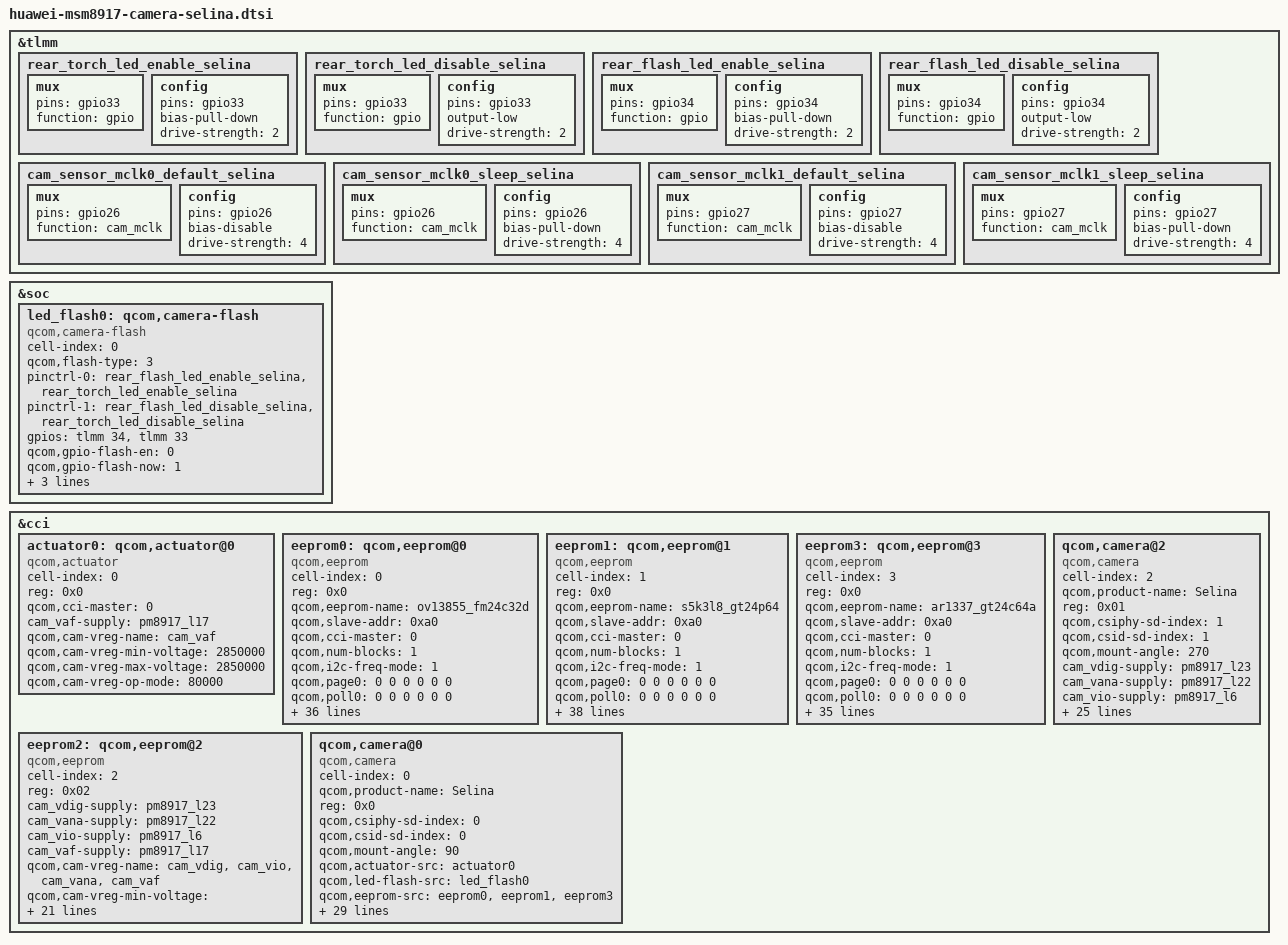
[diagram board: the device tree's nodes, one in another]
/*
 * Copyright (c) 2016, The Linux Foundation. All rights reserved.
 *
 * This program is free software; you can redistribute it and/or modify
 * it under the terms of the GNU General Public License version 2 and
 * only version 2 as published by the Free Software Foundation.
 *
 * This program is distributed in the hope that it will be useful,
 * but WITHOUT ANY WARRANTY; without even the implied warranty of
 * MERCHANTABILITY or FITNESS FOR A PARTICULAR PURPOSE.  See the
 * GNU General Public License for more details.
 */

&tlmm {
	rear_torch_led_enable_selina: rear_torch_led_enable_selina {
		mux {
			pins = "gpio33";
			function = "gpio";
		};

		config {
			pins = "gpio33";
			bias-pull-down; /* No PULL */
			drive-strength = <2>; /* 2 MA */
		};
	};

	rear_torch_led_disable_selina: rear_torch_led_disable_selina {
		mux {
			pins = "gpio33";
			function = "gpio";
		};

		config {
			pins = "gpio33";
			output-low; /* No PULL */
			drive-strength = <2>; /* 2 MA */
		};
	};

	rear_flash_led_enable_selina: rear_flash_led_enable_selina {
		mux {
			pins = "gpio34";
			function = "gpio";
		};

		config {
			pins = "gpio34";
			bias-pull-down; /* No PULL */
			drive-strength = <2>; /* 2 MA */
		};
	};

	rear_flash_led_disable_selina: rear_flash_led_disable_selina {
		mux {
			pins = "gpio34";
			function = "gpio";
		};

		config {
			pins = "gpio34";
			output-low; /* No PULL */
			drive-strength = <2>; /* 2 MA */
		};
	};

	cam_sensor_mclk0_default_selina: cam_sensor_mclk0_default_selina {
		/* MCLK0 */
		mux {
			/* CLK, DATA */
			pins = "gpio26";
			function = "cam_mclk";
		};

		config {
			pins = "gpio26";
			bias-disable; /* No PULL */
			drive-strength = <4>; /* 4 MA */
		};
	};

	cam_sensor_mclk0_sleep_selina: cam_sensor_mclk0_sleep_selina {
		/* MCLK0 */
		mux {
			/* CLK, DATA */
			pins = "gpio26";
			function = "cam_mclk";
		};

		config {
			pins = "gpio26";
			bias-pull-down; /* PULL DOWN */
			drive-strength = <4>; /* 4 MA */
		};
	};

	cam_sensor_mclk1_default_selina: cam_sensor_mclk1_default_selina {
		/* MCLK1 */
		mux {
			/* CLK, DATA */
			pins = "gpio27";
			function = "cam_mclk";
		};

		config {
			pins = "gpio27";
			bias-disable; /* No PULL */
			drive-strength = <4>; /* 4 MA */
		};
	};

	cam_sensor_mclk1_sleep_selina: cam_sensor_mclk1_sleep_selina {
		/* MCLK1 */
		mux {
			/* CLK, DATA */
			pins = "gpio27";
			function = "cam_mclk";
		};

		config {
			pins = "gpio27";
			bias-pull-down; /* PULL DOWN */
			drive-strength = <4>; /* 4 MA */
		};
	};

};

&soc {
	led_flash0: qcom,camera-flash {
		cell-index = <0>;
		compatible = "qcom,camera-flash";
		qcom,flash-type = <3>;
		pinctrl-names = "cam_default", "cam_suspend";
		pinctrl-0 = <&rear_flash_led_enable_selina &rear_torch_led_enable_selina>;
		pinctrl-1 = <&rear_flash_led_disable_selina &rear_torch_led_disable_selina>;
		gpios = <&tlmm 34 0>,
				<&tlmm 33 0>;
		qcom,gpio-flash-en = <0>;
		qcom,gpio-flash-now = <1>;
		qcom,gpio-req-tbl-num = <0 1>;
		qcom,gpio-req-tbl-flags = <0 0>;
		qcom,gpio-req-tbl-label = "FLASH_EN",
			"FLASH_NOW";
	};
};

&cci {
	actuator0: qcom,actuator@0 {
		cell-index = <0>;
		reg = <0x0>;
		compatible = "qcom,actuator";
		qcom,cci-master = <0>;
		cam_vaf-supply = <&pm8917_l17>;
		qcom,cam-vreg-name = "cam_vaf";
		qcom,cam-vreg-min-voltage = <2850000>;
		qcom,cam-vreg-max-voltage = <2850000>;
		qcom,cam-vreg-op-mode = <80000>;
	};

	eeprom0: qcom,eeprom@0 {
		cell-index = <0>;
		reg = <0x0>;
		qcom,eeprom-name = "ov13855_fm24c32d";
		compatible = "qcom,eeprom";

		qcom,slave-addr  = <0xa0>;
		qcom,cci-master = <0>;
		qcom,num-blocks = <1>;
		qcom,i2c-freq-mode = <1>;

		qcom,page0 = <0 0 0 0 0 0>;
		qcom,poll0 = <0 0 0 0 0 0>;
		qcom,mem0  = <2800 0x0000 2 0 1 0>;

		cam_vana-supply = <&pm8917_l22>;
		cam_vdig-supply = <&pm8917_l23>;
		cam_vio-supply = <&pm8917_l6>;
		cam_vaf-supply = <&pm8917_l17>;
		qcom,cam-vreg-name = "cam_vdig", "cam_vio", "cam_vana",
							"cam_vaf";
		qcom,cam-vreg-min-voltage = <1200000 1800000 2800000 2850000>;
		qcom,cam-vreg-max-voltage = <1200000 1800000 2800000 2850000>;
		qcom,cam-vreg-op-mode = <200000 80000 80000 100000>;
		pinctrl-names = "cam_default", "cam_suspend";
		pinctrl-0 = <&cam_sensor_mclk0_default_selina
				&cam_sensor_rear_default>;
		pinctrl-1 = <&cam_sensor_mclk0_sleep_selina &cam_sensor_rear_sleep>;
		gpios = <&tlmm 26 0>,
			<&tlmm 36 0>,
			<&tlmm 35 0>;
		qcom,gpio-reset = <1>;
		qcom,gpio-standby = <2>;
		qcom,gpio-req-tbl-num = <0 1 2>;
		qcom,gpio-req-tbl-flags = <1 0 0>;
		qcom,gpio-req-tbl-label = "CAMIF_MCLK0",
			"CAM_RESET0",
			"CAM_STANDBY0";
		status = "ok";
		qcom,cam-power-seq-type = "sensor_gpio","sensor_vreg","sensor_vreg","sensor_vreg","sensor_vreg",
				"sensor_gpio","sensor_clk";
		qcom,cam-power-seq-val = "sensor_gpio_reset","cam_vio","cam_vana","cam_vdig","cam_vaf",
				"sensor_gpio_reset","sensor_cam_mclk";
		qcom,cam-power-seq-cfg-val = <0 0 0 0 0 1 24000000>;
		qcom,cam-power-seq-delay =   <1 0 0 0 5 5 5 1>;
		clocks = <&clock_gcc clk_mclk0_clk_src>,
				<&clock_gcc clk_gcc_camss_mclk0_clk>;
		clock-names = "cam_src_clk", "cam_clk";
		qcom,clock-rates = <19200000 0>;
	};

	eeprom1: qcom,eeprom@1 {
		cell-index = <1>;
		reg = <0x0>;
		qcom,eeprom-name = "s5k3l8_gt24p64";
		compatible = "qcom,eeprom";

		qcom,slave-addr  = <0xa0>;
		qcom,cci-master = <0>;
		qcom,num-blocks = <1>;
		qcom,i2c-freq-mode = <1>;

		qcom,page0 = <0 0 0 0 0 0>;
		qcom,poll0 = <0 0 0 0 0 0>;
		qcom,mem0  = <2900 0x0000 2 0 1 0>;

		cam_vana-supply = <&pm8917_l22>;
		cam_vdig-supply = <&pm8917_l23>;
		cam_vio-supply = <&pm8917_l6>;
		cam_vaf-supply = <&pm8917_l17>;
		qcom,cam-vreg-name = "cam_vdig", "cam_vio", "cam_vana",
							"cam_vaf";
		qcom,cam-vreg-min-voltage = <1200000 1800000 2800000 2850000>;
		qcom,cam-vreg-max-voltage = <1200000 1800000 2800000 2850000>;
		qcom,cam-vreg-op-mode = <200000 80000 80000 100000>;
		pinctrl-names = "cam_default", "cam_suspend";
		pinctrl-0 = <&cam_sensor_mclk0_default_selina
				&cam_sensor_rear_default>;
		pinctrl-1 = <&cam_sensor_mclk0_sleep_selina &cam_sensor_rear_sleep>;
		gpios = <&tlmm 26 0>,
			<&tlmm 36 0>,
			<&tlmm 35 0>;
		qcom,gpio-reset = <1>;
		qcom,gpio-standby = <2>;
		qcom,gpio-req-tbl-num = <0 1 2>;
		qcom,gpio-req-tbl-flags = <1 0 0>;
		qcom,gpio-req-tbl-label = "CAMIF_MCLK0",
			"CAM_RESET0",
			"CAM_STANDBY0";
		status = "ok";
		qcom,cam-power-seq-type = "sensor_gpio","sensor_gpio","sensor_vreg","sensor_vreg","sensor_vreg",
				"sensor_gpio","sensor_gpio","sensor_clk";
		qcom,cam-power-seq-val = "sensor_gpio_reset","sensor_gpio_standby","cam_vana","cam_vio","cam_vdig",
				"sensor_gpio_reset","sensor_gpio_standby","sensor_cam_mclk";
		qcom,cam-power-seq-cfg-val = <0 0 0 0 0 1 1 24000000>;
		qcom,cam-power-seq-delay =   <1 1 0 0 0 1 0 1>;
		clocks = <&clock_gcc clk_mclk0_clk_src>,
				<&clock_gcc clk_gcc_camss_mclk0_clk>;
		clock-names = "cam_src_clk", "cam_clk";
		qcom,clock-rates = <19200000 0>;
	};

	eeprom3: qcom,eeprom@3 {
		cell-index = <3>;
		reg = <0x0>;
		qcom,eeprom-name = "ar1337_gt24c64a";
		compatible = "qcom,eeprom";

		qcom,slave-addr  = <0xa0>;
		qcom,cci-master = <0>;
		qcom,num-blocks = <1>;
		qcom,i2c-freq-mode = <1>;

		qcom,page0 = <0 0 0 0 0 0>;
		qcom,poll0 = <0 0 0 0 0 0>;
		qcom,mem0  = <2400 0x0000 2 0 1 0>;

		cam_vana-supply = <&pm8917_l22>;
		cam_vdig-supply = <&pm8917_l23>;
		cam_vio-supply = <&pm8917_l6>;
		cam_vaf-supply = <&pm8917_l17>;
		qcom,cam-vreg-name = "cam_vdig", "cam_vio", "cam_vana",
							"cam_vaf";
		qcom,cam-vreg-min-voltage = <1200000 1800000 2800000 2850000>;
		qcom,cam-vreg-max-voltage = <1200000 1800000 2800000 2850000>;
		qcom,cam-vreg-op-mode = <200000 80000 80000 100000>;
		pinctrl-names = "cam_default", "cam_suspend";
		pinctrl-0 = <&cam_sensor_mclk0_default_selina
				&cam_sensor_rear_default>;
		pinctrl-1 = <&cam_sensor_mclk0_sleep_selina &cam_sensor_rear_sleep>;
		gpios = <&tlmm 26 0>,
			<&tlmm 36 0>,
			<&tlmm 35 0>;
		qcom,gpio-reset = <1>;
		qcom,gpio-standby = <2>;
		qcom,gpio-req-tbl-num = <0 1 2>;
		qcom,gpio-req-tbl-flags = <1 0 0>;
		qcom,gpio-req-tbl-label = "CAMIF_MCLK0",
			"CAM_RESET0",
			"CAM_STANDBY0";
		status = "ok";
		qcom,cam-power-seq-type = "sensor_vreg","sensor_vreg","sensor_vreg",
				"sensor_clk","sensor_gpio","sensor_gpio";
		qcom,cam-power-seq-val = "cam_vio","cam_vana","cam_vdig",
				"sensor_cam_mclk","sensor_gpio_standby","sensor_gpio_standby";
		qcom,cam-power-seq-cfg-val = <0 0 0 24000000 0 1>;
		qcom,cam-power-seq-delay =   <1 1 1 10 1 1>;
		clocks = <&clock_gcc clk_mclk0_clk_src>,
				<&clock_gcc clk_gcc_camss_mclk0_clk>;
		clock-names = "cam_src_clk", "cam_clk";
		qcom,clock-rates = <19200000 0>;
	};

	eeprom2: qcom,eeprom@2 {
		cell-index = <2>;
		compatible = "qcom,eeprom";
		reg = <0x02>;
		cam_vdig-supply = <&pm8917_l23>;
		cam_vana-supply = <&pm8917_l22>;
		cam_vio-supply = <&pm8917_l6>;
		cam_vaf-supply = <&pm8917_l17>;
		qcom,cam-vreg-name = "cam_vdig", "cam_vio", "cam_vana",
								"cam_vaf";
		qcom,cam-vreg-min-voltage = <1200000 1800000 2800000 2850000>;
		qcom,cam-vreg-max-voltage = <1200000 1800000 2800000 2850000>;
		qcom,cam-vreg-op-mode = <105000 80000 80000 100000>;
		qcom,gpio-no-mux = <0>;
		pinctrl-names = "cam_default", "cam_suspend";
		pinctrl-0 = <&cam_sensor_mclk2_default
					&cam_sensor_front1_default>;
		pinctrl-1 = <&cam_sensor_mclk2_sleep
					&cam_sensor_front1_sleep>;
		gpios = <&tlmm 28 0>,
			<&tlmm 40 0>,
			<&tlmm 39 0>;
		qcom,gpio-reset = <1>;
		qcom,gpio-standby = <2>;
		qcom,gpio-req-tbl-num = <0 1 2>;
		qcom,gpio-req-tbl-flags = <1 0 0>;
		qcom,gpio-req-tbl-label = "CAMIF_MCLK2",
					  "CAM_RESET2",
					  "CAM_STANDBY2";
		qcom,cci-master = <0>;
		status = "ok";
		clocks = <&clock_gcc clk_mclk2_clk_src>,
			<&clock_gcc clk_gcc_camss_mclk2_clk>;
		clock-names = "cam_src_clk", "cam_clk";
		qcom,clock-rates = <19200000 0>;
	};

	qcom,camera@0 { //ov13855_ohp0351 s5k3l8_sunny ar1337_f1337ad
		cell-index = <0>;
		compatible = "qcom,camera";
		qcom,product-name = "Selina";
		reg = <0x0>;
		qcom,csiphy-sd-index = <0>;
		qcom,csid-sd-index = <0>;
		qcom,mount-angle = <90>;
		qcom,actuator-src = <&actuator0>;
		qcom,led-flash-src = <&led_flash0>;
		qcom,eeprom-src = <&eeprom0 &eeprom1 &eeprom3>;
		cam_vana-supply = <&pm8917_l22>;
		cam_vdig-supply = <&pm8917_l23>;
		cam_vio-supply = <&pm8917_l6>;
		cam_vaf-supply = <&pm8917_l17>;
		qcom,cam-vreg-name = "cam_vdig", "cam_vio", "cam_vana",
							"cam_vaf";
		qcom,cam-vreg-min-voltage = <1200000 1800000 2800000 2850000>;
		qcom,cam-vreg-max-voltage = <1200000 1800000 2800000 2850000>;
		qcom,cam-vreg-op-mode = <200000 80000 80000 100000>;
		pinctrl-names = "cam_default", "cam_suspend";
		pinctrl-0 = <&cam_sensor_mclk0_default_selina
				&cam_sensor_rear_default>;
		pinctrl-1 = <&cam_sensor_mclk0_sleep_selina
				&cam_sensor_rear_sleep>;
		gpios = <&tlmm 26 0>,
			<&tlmm 36 0>,
			<&tlmm 35 0>;
		qcom,gpio-reset = <1>;
		qcom,gpio-standby = <2>;
		qcom,gpio-req-tbl-num = <0 1 2>;
		qcom,gpio-req-tbl-flags = <1 0 0>;
		qcom,gpio-req-tbl-label = "CAMIF_MCLK0",
			"CAM_RESET0",
			"CAM_STANDBY0";
		qcom,sensor-position = <0>;
		qcom,sensor-mode = <0>;
		qcom,cci-master = <0>;
		clocks = <&clock_gcc clk_mclk0_clk_src>,
			<&clock_gcc clk_gcc_camss_mclk0_clk>;
		clock-names = "cam_src_clk", "cam_clk";
		qcom,clock-rates = <24000000 0>;
	};

	qcom,camera@2 { //hi553
		cell-index = <2>;
		compatible = "qcom,camera";
		qcom,product-name = "Selina";
		reg = <0x01>;
		qcom,csiphy-sd-index = <1>;
		qcom,csid-sd-index = <1>;
		//qcom,eeprom-src = <&eeprom2>;//otp add
		qcom,mount-angle = <270>;
		cam_vdig-supply = <&pm8917_l23>;
		cam_vana-supply = <&pm8917_l22>;
		cam_vio-supply = <&pm8917_l6>;
		qcom,cam-vreg-name = "cam_vdig", "cam_vio", "cam_vana";
		qcom,cam-vreg-min-voltage = <1200000 1800000 2800000>;
		qcom,cam-vreg-max-voltage = <1200000 1800000 2800000>;
		qcom,cam-vreg-op-mode = <105000 80000 80000>;
		qcom,gpio-no-mux = <0>;
		pinctrl-names = "cam_default", "cam_suspend";
		pinctrl-0 = <&cam_sensor_mclk1_default_selina
				&cam_sensor_front1_default>;
		pinctrl-1 = <&cam_sensor_mclk1_sleep_selina
				&cam_sensor_front1_sleep>;
		gpios = <&tlmm 27 0>,
			<&tlmm 40 0>,
			<&tlmm 39 0>;
		qcom,gpio-reset = <1>;
		qcom,gpio-standby = <2>;
		qcom,gpio-req-tbl-num = <0 1 2>;
		qcom,gpio-req-tbl-flags = <1 0 0>;
		qcom,gpio-req-tbl-label = "CAMIF_MCLK1",
					  "CAM_RESET2",
					  "CAM_STANDBY2";
		qcom,sensor-position = <1>;
		qcom,sensor-mode = <1>;
		qcom,cci-master = <1>;
		clocks = <&clock_gcc clk_mclk1_clk_src>,
			<&clock_gcc clk_gcc_camss_mclk1_clk>;
		clock-names = "cam_src_clk", "cam_clk";
		qcom,clock-rates = <24000000 0>;
	};
};
